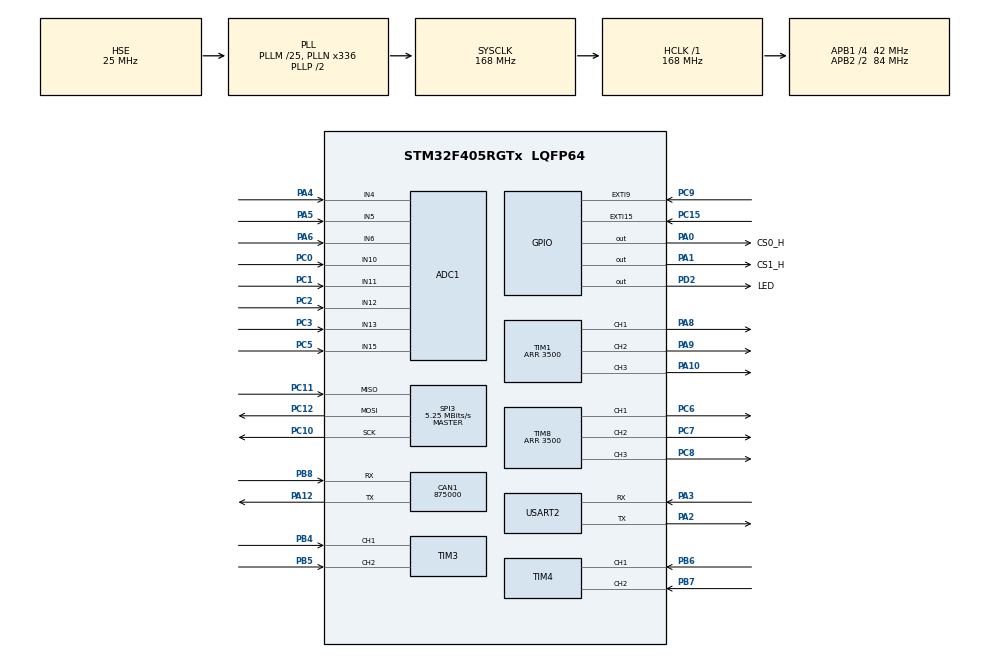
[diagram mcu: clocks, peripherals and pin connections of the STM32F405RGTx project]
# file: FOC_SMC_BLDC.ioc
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ADC1.Channel-0\#ChannelRegularConversion=ADC_CHANNEL_10
ADC1.ExternalTrigConv=ADC_SOFTWARE_START
ADC1.NbrOfConversion=1
ADC1.NbrOfConversionFlag=1
ADC1.Rank-0\#ChannelRegularConversion=1
ADC1.SamplingTime-0\#ChannelRegularConversion=ADC_SAMPLETIME_3CYCLES
ADC1.ScanConvMode=ENABLE
ADC1.master=1
ADC2.Channel-0\#ChannelRegularConversion=ADC_CHANNEL_13
ADC2.ExternalTrigConv=ADC_EXTERNALTRIGCONV_T8_TRGO
ADC2.NbrOfConversionFlag=1
ADC2.Rank-0\#ChannelRegularConversion=1
ADC2.SamplingTime-0\#ChannelRegularConversion=ADC_SAMPLETIME_3CYCLES
ADC3.Channel-0\#ChannelRegularConversion=ADC_CHANNEL_11
ADC3.ExternalTrigConv=ADC_EXTERNALTRIGCONV_T8_TRGO
ADC3.NbrOfConversionFlag=1
ADC3.Rank-0\#ChannelRegularConversion=1
ADC3.SamplingTime-0\#ChannelRegularConversion=ADC_SAMPLETIME_3CYCLES
CAN1.CalculateBaudRate=875000
CAN1.CalculateTimeBit=1142
CAN1.CalculateTimeQuantum=380.95238095238096
Dma.Request0=USART2_RX
Dma.Request1=USART2_TX
Dma.USART2_RX.0.Direction=DMA_PERIPH_TO_MEMORY
Dma.USART2_RX.0.FIFOMode=DMA_FIFOMODE_DISABLE
Dma.USART2_RX.0.Instance=DMA1_Stream5
Dma.USART2_RX.0.MemDataAlignment=DMA_MDATAALIGN_BYTE
Dma.USART2_RX.0.MemInc=DMA_MINC_ENABLE
Dma.USART2_RX.0.Mode=DMA_CIRCULAR
Dma.USART2_RX.0.PeriphDataAlignment=DMA_PDATAALIGN_BYTE
Dma.USART2_RX.0.PeriphInc=DMA_PINC_DISABLE
Dma.USART2_RX.0.Priority=DMA_PRIORITY_MEDIUM
Dma.USART2_TX.1.Direction=DMA_MEMORY_TO_PERIPH
Dma.USART2_TX.1.FIFOMode=DMA_FIFOMODE_DISABLE
Dma.USART2_TX.1.Instance=DMA1_Stream6
Dma.USART2_TX.1.MemDataAlignment=DMA_MDATAALIGN_BYTE
Dma.USART2_TX.1.MemInc=DMA_MINC_ENABLE
Dma.USART2_TX.1.Mode=DMA_NORMAL
Dma.USART2_TX.1.PeriphDataAlignment=DMA_PDATAALIGN_BYTE
Dma.USART2_TX.1.PeriphInc=DMA_PINC_DISABLE
Dma.USART2_TX.1.Priority=DMA_PRIORITY_MEDIUM
Mcu.Family=STM32F4
Mcu.Name=STM32F405RGTx
Mcu.Package=LQFP64
NVIC.ADC_IRQn=true\:0\:0\:false\:false\:true\:true\:true
NVIC.DMA1_Stream5_IRQn=true\:1\:0\:true\:false\:true\:false\:true
NVIC.DMA1_Stream6_IRQn=true\:1\:0\:true\:false\:true\:false\:true
NVIC.EXTI15_10_IRQn=true\:1\:0\:true\:false\:true\:true\:true
NVIC.EXTI9_5_IRQn=true\:1\:0\:true\:false\:true\:true\:true
NVIC.PriorityGroup=NVIC_PRIORITYGROUP_4
NVIC.TIM1_TRG_COM_TIM11_IRQn=true\:0\:0\:false\:false\:true\:true\:true
NVIC.USART2_IRQn=true\:0\:0\:true\:false\:true\:true\:true
PA0-WKUP.GPIO_Label=CS0_H
PA0-WKUP.GPIO_PuPd=GPIO_PULLUP
PA0-WKUP.GPIO_Speed=GPIO_SPEED_FREQ_HIGH
PA0-WKUP.PinState=GPIO_PIN_SET
PA0-WKUP.Signal=GPIO_Output
PA1.GPIO_Label=CS1_H
PA1.GPIO_PuPd=GPIO_PULLUP
PA1.GPIO_Speed=GPIO_SPEED_FREQ_HIGH
PA1.PinState=GPIO_PIN_SET
PA1.Signal=GPIO_Output
PA10.Signal=S_TIM1_CH3
PA12.Mode=CAN_Activate
PA12.Signal=CAN1_TX
PA13.Mode=Serial_Wire
PA13.Signal=SYS_JTMS-SWDIO
PA14.Mode=Serial_Wire
PA14.Signal=SYS_JTCK-SWCLK
PA2.GPIO_PuPd=GPIO_PULLUP
PA2.Mode=Asynchronous
PA2.Signal=USART2_TX
PA3.GPIO_PuPd=GPIO_PULLUP
PA3.Mode=Asynchronous
PA3.Signal=USART2_RX
PA4.Signal=ADCx_IN4
PA5.Signal=ADCx_IN5
PA6.Signal=ADCx_IN6
PA8.Signal=S_TIM1_CH1
PA9.Signal=S_TIM1_CH2
PB4.Signal=S_TIM3_CH1
PB5.Signal=S_TIM3_CH2
PB6.Signal=S_TIM4_CH1
PB7.Signal=S_TIM4_CH2
PB8.Mode=CAN_Activate
PB8.Signal=CAN1_RX
PC0.Signal=ADCx_IN10
PC1.Signal=ADCx_IN11
PC10.Mode=Full_Duplex_Master
PC10.Signal=SPI3_SCK
PC11.Mode=Full_Duplex_Master
PC11.Signal=SPI3_MISO
PC12.Mode=Full_Duplex_Master
PC12.Signal=SPI3_MOSI
PC15-OSC32_OUT.Signal=GPXTI15
PC2.Signal=ADCx_IN12
PC3.Signal=ADCx_IN13
PC5.Signal=ADCx_IN15
PC6.Signal=S_TIM8_CH1
PC7.Signal=S_TIM8_CH2
PC8.Signal=S_TIM8_CH3
PC9.Signal=GPXTI9
PD2.GPIO_Label=LED
PD2.Signal=GPIO_Output
PH0-OSC_IN.Mode=HSE-External-Oscillator
PH0-OSC_IN.Signal=RCC_OSC_IN
PH1-OSC_OUT.Mode=HSE-External-Oscillator
PH1-OSC_OUT.Signal=RCC_OSC_OUT
ProjectManager.HeapSize=0x200
ProjectManager.StackSize=0x400
ProjectManager.TargetToolchain=SW4STM32
RCC.48MHZClocksFreq_Value=84000000
RCC.AHBFreq_Value=168000000
RCC.APB1CLKDivider=RCC_HCLK_DIV4
RCC.APB1Freq_Value=42000000
RCC.APB1TimFreq_Value=84000000
RCC.APB2CLKDivider=RCC_HCLK_DIV2
RCC.APB2Freq_Value=84000000
RCC.APB2TimFreq_Value=168000000
RCC.CortexFreq_Value=168000000
RCC.HCLKFreq_Value=168000000
RCC.HSE_VALUE=25000000
RCC.HSI_VALUE=16000000
RCC.LSE_VALUE=32768
RCC.PLLM=25
RCC.PLLN=336
RCC.PLLSourceVirtual=RCC_PLLSOURCE_HSE
RCC.SYSCLKFreq_VALUE=168000000
RCC.SYSCLKSource=RCC_SYSCLKSOURCE_PLLCLK
RCC.VCOOutputFreq_Value=336000000
SH.ADCx_IN10.0=ADC1_IN10,IN10
SH.ADCx_IN10.1=ADC2_IN10,IN10
SH.ADCx_IN11.0=ADC1_IN11,IN11
SH.ADCx_IN11.1=ADC3_IN11,IN11
SH.ADCx_IN12.0=ADC1_IN12,IN12
SH.ADCx_IN12.1=ADC3_IN12,IN12
SH.ADCx_IN13.0=ADC1_IN13,IN13
SH.ADCx_IN13.1=ADC2_IN13,IN13
SH.ADCx_IN15.0=ADC1_IN15,IN15
SH.ADCx_IN4.0=ADC1_IN4,IN4
SH.ADCx_IN5.0=ADC1_IN5,IN5
SH.ADCx_IN6.0=ADC1_IN6,IN6
SH.S_TIM1_CH1.0=TIM1_CH1,PWM Generation1 CH1
SH.S_TIM1_CH2.0=TIM1_CH2,PWM Generation2 CH2
SH.S_TIM1_CH3.0=TIM1_CH3,PWM Generation3 CH3
SH.S_TIM3_CH1.0=TIM3_CH1,Encoder_Interface
SH.S_TIM3_CH2.0=TIM3_CH2,Encoder_Interface
SH.S_TIM4_CH1.0=TIM4_CH1,Encoder_Interface
SH.S_TIM4_CH2.0=TIM4_CH2,Encoder_Interface
SH.S_TIM8_CH1.0=TIM8_CH1,PWM Generation1 CH1
SH.S_TIM8_CH2.0=TIM8_CH2,PWM Generation2 CH2
SH.S_TIM8_CH3.0=TIM8_CH3,PWM Generation3 CH3
SPI3.BaudRatePrescaler=SPI_BAUDRATEPRESCALER_8
SPI3.CRCCalculation=SPI_CRCCALCULATION_DISABLE
SPI3.CalculateBaudRate=5.25 MBits/s
SPI3.DataSize=SPI_DATASIZE_16BIT
SPI3.Direction=SPI_DIRECTION_2LINES
SPI3.Mode=SPI_MODE_MASTER
SPI3.VirtualType=VM_MASTER
TIM1.AutoReloadPreload=TIM_AUTORELOAD_PRELOAD_ENABLE
TIM1.BreakState=TIM_BREAK_ENABLE
TIM1.Channel-PWM\ Generation1\ CH1=TIM_CHANNEL_1
TIM1.Channel-PWM\ Generation2\ CH2=TIM_CHANNEL_2
TIM1.Channel-PWM\ Generation3\ CH3=TIM_CHANNEL_3
TIM1.OffStateIDLEMode=TIM_OSSI_ENABLE
TIM1.OffStateRunMode=TIM_OSSR_ENABLE
TIM1.Period=3500
TIM1.RepetitionCounter=2
TIM3.AutoReloadPreload=TIM_AUTORELOAD_PRELOAD_ENABLE
TIM3.EncoderMode=TIM_ENCODERMODE_TI12
TIM3.IC1Filter=4
TIM3.IC2Filter=4
TIM4.AutoReloadPreload=TIM_AUTORELOAD_PRELOAD_ENABLE
TIM4.EncoderMode=TIM_ENCODERMODE_TI12
TIM4.IC1Filter=4
TIM4.IC2Filter=4
TIM8.AutoReloadPreload=TIM_AUTORELOAD_PRELOAD_ENABLE
TIM8.Channel-PWM\ Generation1\ CH1=TIM_CHANNEL_1
TIM8.Channel-PWM\ Generation2\ CH2=TIM_CHANNEL_2
TIM8.Channel-PWM\ Generation3\ CH3=TIM_CHANNEL_3
TIM8.OffStateIDLEMode=TIM_OSSI_ENABLE
TIM8.OffStateRunMode=TIM_OSSR_ENABLE
TIM8.Period=3500
USART2.VirtualMode=VM_ASYNC
VP_ADC1_TempSens_Input.Mode=IN-TempSens
VP_TIM1_VS_ClockSourceINT.Mode=Internal
VP_TIM8_VS_ClockSourceINT.Mode=Internal
board=custom

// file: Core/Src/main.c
/* USER CODE BEGIN Header */
/**
  ******************************************************************************
  * @file           : main.c
  * @brief          : Main program body
  ******************************************************************************
  * @attention
  *
  * Copyright (c) 2023 STMicroelectronics.
  * All rights reserved.
  *
  * This software is licensed under terms that can be found in the LICENSE file
  * in the root directory of this software component.
  * If no LICENSE file comes with this software, it is provided AS-IS.
  *
  ******************************************************************************
  */
/* USER CODE END Header */
#include "main.h"
#include "adc.h"
#include "can.h"
#include "dma.h"
#include "spi.h"
#include "tim.h"
#include "usart.h"
#include "gpio.h"

/* USER CODE BEGIN Includes */
#include "common_inc.h"
#include "stdio.h"

/* USER CODE END Includes */

/* USER CODE BEGIN PD */
#define LED_blink   GPIOD->ODR^=(1<<2)  //PD2

/* USER CODE END PD */

void SystemClock_Config(void);

int main(void)
{

  /* MCU Configuration--------------------------------------------------------*/

  /* Reset of all peripherals, Initializes the Flash interface and the Systick. */
  HAL_Init();

  /* Configure the system clock */
  SystemClock_Config();

  /* Initialize all configured peripherals */
  MX_GPIO_Init();
  MX_ADC1_Init();
    MX_DMA_Init();
  MX_TIM1_Init();
  MX_CAN1_Init();
  MX_SPI3_Init();
  MX_TIM8_Init();
  MX_USART2_UART_Init();
  MX_TIM3_Init();
  MX_TIM4_Init();
  MX_ADC2_Init();
  MX_ADC3_Init();
  /* USER CODE BEGIN 2 */
    Main();

  /* USER CODE END 2 */

  /* Infinite loop */
  while (1)
  {

  }
}

void SystemClock_Config(void)
{
  RCC_OscInitTypeDef RCC_OscInitStruct = {0};
  RCC_ClkInitTypeDef RCC_ClkInitStruct = {0};

  /** Configure the main internal regulator output voltage
  */
  __HAL_RCC_PWR_CLK_ENABLE();
  __HAL_PWR_VOLTAGESCALING_CONFIG(PWR_REGULATOR_VOLTAGE_SCALE1);
  /** Initializes the RCC Oscillators according to the specified parameters
  * in the RCC_OscInitTypeDef structure.
  */
  RCC_OscInitStruct.OscillatorType = RCC_OSCILLATORTYPE_HSE;
  RCC_OscInitStruct.HSEState = RCC_HSE_ON;
  RCC_OscInitStruct.PLL.PLLState = RCC_PLL_ON;
  RCC_OscInitStruct.PLL.PLLSource = RCC_PLLSOURCE_HSE;
  RCC_OscInitStruct.PLL.PLLM = 25;
  RCC_OscInitStruct.PLL.PLLN = 336;
  RCC_OscInitStruct.PLL.PLLP = RCC_PLLP_DIV2;
  RCC_OscInitStruct.PLL.PLLQ = 4;
  if (HAL_RCC_OscConfig(&RCC_OscInitStruct) != HAL_OK)
  {
    Error_Handler();
  }
  /** Initializes the CPU, AHB and APB buses clocks
  */
  RCC_ClkInitStruct.ClockType = RCC_CLOCKTYPE_HCLK|RCC_CLOCKTYPE_SYSCLK
                              |RCC_CLOCKTYPE_PCLK1|RCC_CLOCKTYPE_PCLK2;
  RCC_ClkInitStruct.SYSCLKSource = RCC_SYSCLKSOURCE_PLLCLK;
  RCC_ClkInitStruct.AHBCLKDivider = RCC_SYSCLK_DIV1;
  RCC_ClkInitStruct.APB1CLKDivider = RCC_HCLK_DIV4;
  RCC_ClkInitStruct.APB2CLKDivider = RCC_HCLK_DIV2;

  if (HAL_RCC_ClockConfig(&RCC_ClkInitStruct, FLASH_LATENCY_5) != HAL_OK)
  {
    Error_Handler();
  }
}

/* USER CODE BEGIN 4 */
int fputc(int ch, FILE *f)
{
    HAL_UART_Transmit(&huart2, (uint8_t*)&ch, 1,HAL_MAX_DELAY);
    return ch;
}

int fgetc(FILE *f)
{
    uint8_t ch = 0;
    HAL_UART_Receive(&huart2, &ch, 1, 0xffff);
    return ch;
}

/* USER CODE END 4 */

void Error_Handler(void)
{
  __disable_irq();
  while (1)
  {
  }
}
